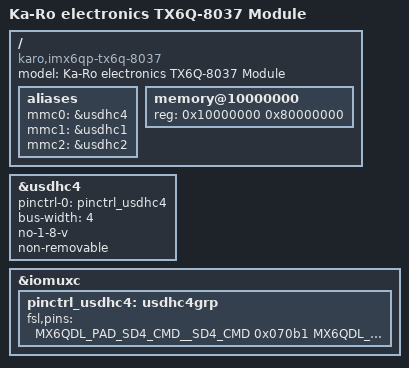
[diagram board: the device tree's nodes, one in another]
// SPDX-License-Identifier: GPL-2.0+
/*
 * Copyright (C) 2026 Ka-Ro Electronics GmbH
 * Ka-Ro TX6Q-8037 module (i.MX6QP, 2 GiB DDR3, 4 GiB eMMC)
 */

/dts-v1/;

#include "imx6qp.dtsi"
#include "imx6qdl-tx6.dtsi"

/ {
	model = "Ka-Ro electronics TX6Q-8037 Module";
	compatible = "karo,imx6qp-tx6q-8037", "karo,imx6qp-tx6q", "fsl,imx6qp";

	/* imx8mp-karo.dtsi: the eMMC is mmc0 in the module DT */
	aliases {
		mmc0 = &usdhc4;
		mmc1 = &usdhc1;
		mmc2 = &usdhc2;
		/delete-property/ mmc3;
	};

	memory@10000000 {
		device_type = "memory";
		reg = <0x10000000 0x80000000>; /* 2 GiB */
	};
};

&usdhc4 {
	pinctrl-names = "default";
	pinctrl-0 = <&pinctrl_usdhc4>;
	bus-width = <4>;
	no-1-8-v;
	non-removable;
	status = "okay";
};

&iomuxc {
	pinctrl_usdhc4: usdhc4grp {
		fsl,pins = <
			MX6QDL_PAD_SD4_CMD__SD4_CMD		0x070b1
			MX6QDL_PAD_SD4_CLK__SD4_CLK		0x070b1
			MX6QDL_PAD_SD4_DAT0__SD4_DATA0		0x070b1
			MX6QDL_PAD_SD4_DAT1__SD4_DATA1		0x070b1
			MX6QDL_PAD_SD4_DAT2__SD4_DATA2		0x070b1
			MX6QDL_PAD_SD4_DAT3__SD4_DATA3		0x070b1
			MX6QDL_PAD_NANDF_ALE__SD4_RESET		0x0b0b1
		>;
	};
};
